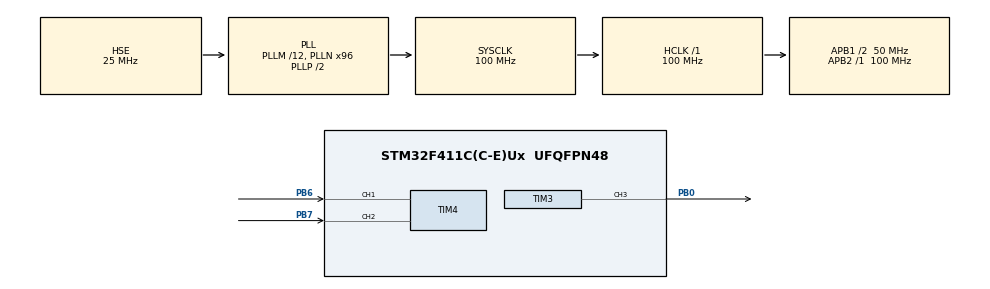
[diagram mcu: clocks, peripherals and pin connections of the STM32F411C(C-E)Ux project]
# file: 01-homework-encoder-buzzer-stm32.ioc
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Mcu.Family=STM32F4
Mcu.Name=STM32F411C(C-E)Ux
Mcu.Package=UFQFPN48
NVIC.PriorityGroup=NVIC_PRIORITYGROUP_4
PA13.Mode=Serial_Wire
PA13.Signal=SYS_JTMS-SWDIO
PA14.Mode=Serial_Wire
PA14.Signal=SYS_JTCK-SWCLK
PB0.Signal=S_TIM3_CH3
PB6.GPIO_PuPd=GPIO_PULLUP
PB6.Signal=S_TIM4_CH1
PB7.GPIO_PuPd=GPIO_PULLUP
PB7.Signal=S_TIM4_CH2
PH0\ -\ OSC_IN.Mode=HSE-External-Oscillator
PH0\ -\ OSC_IN.Signal=RCC_OSC_IN
PH1\ -\ OSC_OUT.Mode=HSE-External-Oscillator
PH1\ -\ OSC_OUT.Signal=RCC_OSC_OUT
ProjectManager.HeapSize=0x200
ProjectManager.StackSize=0x400
ProjectManager.TargetToolchain=STM32CubeIDE
RCC.48MHZClocksFreq_Value=50000000
RCC.AHBFreq_Value=100000000
RCC.APB1CLKDivider=RCC_HCLK_DIV2
RCC.APB1Freq_Value=50000000
RCC.APB1TimFreq_Value=100000000
RCC.APB2Freq_Value=100000000
RCC.APB2TimFreq_Value=100000000
RCC.CortexFreq_Value=100000000
RCC.HCLKFreq_Value=100000000
RCC.HSE_VALUE=25000000
RCC.HSI_VALUE=16000000
RCC.LSE_VALUE=32768
RCC.PLLM=12
RCC.PLLN=96
RCC.PLLSourceVirtual=RCC_PLLSOURCE_HSE
RCC.SYSCLKFreq_VALUE=100000000
RCC.SYSCLKSource=RCC_SYSCLKSOURCE_PLLCLK
RCC.VCOOutputFreq_Value=200000000
SH.S_TIM3_CH3.0=TIM3_CH3,PWM Generation3 CH3
SH.S_TIM4_CH1.0=TIM4_CH1,Encoder_Interface
SH.S_TIM4_CH2.0=TIM4_CH2,Encoder_Interface
TIM3.AutoReloadPreload=TIM_AUTORELOAD_PRELOAD_ENABLE
TIM3.Channel-PWM\ Generation3\ CH3=TIM_CHANNEL_3
TIM3.Period=999
TIM3.Prescaler=99
TIM3.Pulse-PWM\ Generation3\ CH3=500
board=custom

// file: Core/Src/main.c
/* USER CODE BEGIN Header */
/**
  ******************************************************************************
  * @file           : main.c
  * @brief          : Main program body
  ******************************************************************************
  * @attention
  *
  * Copyright (c) 2026 STMicroelectronics.
  * All rights reserved.
  *
  * This software is licensed under terms that can be found in the LICENSE file
  * in the root directory of this software component.
  * If no LICENSE file comes with this software, it is provided AS-IS.
  *
  ******************************************************************************
  */
/* USER CODE END Header */
#include "main.h"

/* USER CODE BEGIN PD */
#define BUZZER_TICK_HZ    1000000   // TIM3 counts at 1 MHz (100 MHz / (PSC 99 + 1))
#define BUZZER_START_ARR  999       // ARR 999 = a 1000 us period = 1 kHz
#define BUZZER_ARR_STEP   5         // ARR taken off per encoder count: counting up raises the tone, down lowers it
#define MELODY_POSITION   120       // about 3.3 turns up (measured: 108 counts in 3 turns): 2.5 kHz, then the melody
#define NOTE_GAP_MS       30        // silence after each note, so repeated notes (E E E) don't merge into one

// Notes of the 6th octave, in Hz
#define NOTE_C6  1047
#define NOTE_D6  1175
#define NOTE_E6  1319
#define NOTE_F6  1397
#define NOTE_G6  1568

// Note lengths, in ms
#define QUARTER         300
#define DOTTED_QUARTER  450
#define EIGHTH          150
#define HALF            600
#define WHOLE          1200
/* USER CODE END PD */

TIM_HandleTypeDef htim3;
TIM_HandleTypeDef htim4;

void SystemClock_Config(void);
static void MX_GPIO_Init(void);
static void MX_TIM3_Init(void);
static void MX_TIM4_Init(void);

/* USER CODE BEGIN 0 */
typedef struct {
  uint16_t hz;   // pitch
  uint16_t ms;   // length, the gap after it included
} Note;

// "Jingle Bells" (1857, public domain), the chorus twice
static const Note jingle_bells[] = {
  {NOTE_E6, QUARTER}, {NOTE_E6, QUARTER}, {NOTE_E6, HALF},
  {NOTE_E6, QUARTER}, {NOTE_E6, QUARTER}, {NOTE_E6, HALF},
  {NOTE_E6, QUARTER}, {NOTE_G6, QUARTER}, {NOTE_C6, DOTTED_QUARTER}, {NOTE_D6, EIGHTH},
  {NOTE_E6, WHOLE},
  {NOTE_F6, QUARTER}, {NOTE_F6, QUARTER}, {NOTE_F6, DOTTED_QUARTER}, {NOTE_F6, EIGHTH},
  {NOTE_F6, QUARTER}, {NOTE_E6, QUARTER}, {NOTE_E6, QUARTER}, {NOTE_E6, EIGHTH}, {NOTE_E6, EIGHTH},
  {NOTE_E6, QUARTER}, {NOTE_D6, QUARTER}, {NOTE_D6, QUARTER}, {NOTE_E6, QUARTER},
  {NOTE_D6, HALF}, {NOTE_G6, HALF},
  {NOTE_E6, QUARTER}, {NOTE_E6, QUARTER}, {NOTE_E6, HALF},
  {NOTE_E6, QUARTER}, {NOTE_E6, QUARTER}, {NOTE_E6, HALF},
  {NOTE_E6, QUARTER}, {NOTE_G6, QUARTER}, {NOTE_C6, DOTTED_QUARTER}, {NOTE_D6, EIGHTH},
  {NOTE_E6, WHOLE},
  {NOTE_F6, QUARTER}, {NOTE_F6, QUARTER}, {NOTE_F6, QUARTER}, {NOTE_F6, QUARTER},
  {NOTE_F6, QUARTER}, {NOTE_E6, QUARTER}, {NOTE_E6, QUARTER}, {NOTE_E6, EIGHTH}, {NOTE_E6, EIGHTH},
  {NOTE_G6, QUARTER}, {NOTE_G6, QUARTER}, {NOTE_F6, QUARTER}, {NOTE_D6, QUARTER},
  {NOTE_C6, WHOLE},
};

// Sets the buzzer's period in TIM3 ticks (1 us each) and keeps the duty at 50 %
static void buzzer_set_arr(uint32_t arr)
{
  __HAL_TIM_SET_AUTORELOAD(&htim3, arr);                          // preload on: starts when the current period ends
  __HAL_TIM_SET_COMPARE(&htim3, TIM_CHANNEL_3, (arr + 1) / 2);    // high for half the period
}

// Plays the whole melody; blocks for about 19 s, while TIM4 keeps counting the knob by itself
static void play_melody(void)
{
  for (uint32_t i = 0; i < sizeof(jingle_bells) / sizeof(jingle_bells[0]); i++) {
    buzzer_set_arr(BUZZER_TICK_HZ / jingle_bells[i].hz - 1);   // f = 1 MHz / (ARR + 1)
    HAL_Delay(jingle_bells[i].ms - NOTE_GAP_MS);
    __HAL_TIM_SET_COMPARE(&htim3, TIM_CHANNEL_3, 0);           // CCR 0: PB0 stays low, silence
    HAL_Delay(NOTE_GAP_MS);
  }
}
/* USER CODE END 0 */

int main(void)
{

  /* MCU Configuration--------------------------------------------------------*/

  /* Reset of all peripherals, Initializes the Flash interface and the Systick. */
  HAL_Init();

  /* Configure the system clock */
  SystemClock_Config();

  /* Initialize all configured peripherals */
  MX_GPIO_Init();
  MX_TIM3_Init();
  MX_TIM4_Init();
  /* USER CODE BEGIN 2 */
  HAL_TIM_PWM_Start(&htim3, TIM_CHANNEL_3);         // the buzzer: TIM3 drives PB0 by itself from now on
  HAL_TIM_Encoder_Start(&htim4, TIM_CHANNEL_ALL);   // the knob: TIM4 counts PB6/PB7 edges up or down by itself

  /* USER CODE END 2 */

  /* Infinite loop */
  while (1)
  {

    /* USER CODE BEGIN 3 */
    // TIM4's counter = where the knob is. Read as signed: one count below the start is -1, not 65535
    int16_t knob_position = (int16_t)__HAL_TIM_GET_COUNTER(&htim4);
    if (knob_position >= MELODY_POSITION) {
      play_melody();   // and again on the next pass, while the knob stays there
    } else {
      buzzer_set_arr(BUZZER_START_ARR - knob_position * BUZZER_ARR_STEP);   // smaller ARR = shorter period = higher tone
    }
  }
  /* USER CODE END 3 */
}

void SystemClock_Config(void)
{
  RCC_OscInitTypeDef RCC_OscInitStruct = {0};
  RCC_ClkInitTypeDef RCC_ClkInitStruct = {0};

  /** Configure the main internal regulator output voltage
  */
  __HAL_RCC_PWR_CLK_ENABLE();
  __HAL_PWR_VOLTAGESCALING_CONFIG(PWR_REGULATOR_VOLTAGE_SCALE1);

  /** Initializes the RCC Oscillators according to the specified parameters
  * in the RCC_OscInitTypeDef structure.
  */
  RCC_OscInitStruct.OscillatorType = RCC_OSCILLATORTYPE_HSE;
  RCC_OscInitStruct.HSEState = RCC_HSE_ON;
  RCC_OscInitStruct.PLL.PLLState = RCC_PLL_ON;
  RCC_OscInitStruct.PLL.PLLSource = RCC_PLLSOURCE_HSE;
  RCC_OscInitStruct.PLL.PLLM = 12;
  RCC_OscInitStruct.PLL.PLLN = 96;
  RCC_OscInitStruct.PLL.PLLP = RCC_PLLP_DIV2;
  RCC_OscInitStruct.PLL.PLLQ = 4;
  if (HAL_RCC_OscConfig(&RCC_OscInitStruct) != HAL_OK)
  {
    Error_Handler();
  }

  /** Initializes the CPU, AHB and APB buses clocks
  */
  RCC_ClkInitStruct.ClockType = RCC_CLOCKTYPE_HCLK|RCC_CLOCKTYPE_SYSCLK
                              |RCC_CLOCKTYPE_PCLK1|RCC_CLOCKTYPE_PCLK2;
  RCC_ClkInitStruct.SYSCLKSource = RCC_SYSCLKSOURCE_PLLCLK;
  RCC_ClkInitStruct.AHBCLKDivider = RCC_SYSCLK_DIV1;
  RCC_ClkInitStruct.APB1CLKDivider = RCC_HCLK_DIV2;
  RCC_ClkInitStruct.APB2CLKDivider = RCC_HCLK_DIV1;

  if (HAL_RCC_ClockConfig(&RCC_ClkInitStruct, FLASH_LATENCY_3) != HAL_OK)
  {
    Error_Handler();
  }
}

static void MX_TIM3_Init(void)
{

  TIM_MasterConfigTypeDef sMasterConfig = {0};
  TIM_OC_InitTypeDef sConfigOC = {0};

  htim3.Instance = TIM3;
  htim3.Init.Prescaler = 99;
  htim3.Init.CounterMode = TIM_COUNTERMODE_UP;
  htim3.Init.Period = 999;
  htim3.Init.ClockDivision = TIM_CLOCKDIVISION_DIV1;
  htim3.Init.AutoReloadPreload = TIM_AUTORELOAD_PRELOAD_ENABLE;
  if (HAL_TIM_PWM_Init(&htim3) != HAL_OK)
  {
    Error_Handler();
  }
  sMasterConfig.MasterOutputTrigger = TIM_TRGO_RESET;
  sMasterConfig.MasterSlaveMode = TIM_MASTERSLAVEMODE_DISABLE;
  if (HAL_TIMEx_MasterConfigSynchronization(&htim3, &sMasterConfig) != HAL_OK)
  {
    Error_Handler();
  }
  sConfigOC.OCMode = TIM_OCMODE_PWM1;
  sConfigOC.Pulse = 500;
  sConfigOC.OCPolarity = TIM_OCPOLARITY_HIGH;
  sConfigOC.OCFastMode = TIM_OCFAST_DISABLE;
  if (HAL_TIM_PWM_ConfigChannel(&htim3, &sConfigOC, TIM_CHANNEL_3) != HAL_OK)
  {
    Error_Handler();
  }
  HAL_TIM_MspPostInit(&htim3);

}

static void MX_TIM4_Init(void)
{

  TIM_Encoder_InitTypeDef sConfig = {0};
  TIM_MasterConfigTypeDef sMasterConfig = {0};

  htim4.Instance = TIM4;
  htim4.Init.Prescaler = 0;
  htim4.Init.CounterMode = TIM_COUNTERMODE_UP;
  htim4.Init.Period = 65535;
  htim4.Init.ClockDivision = TIM_CLOCKDIVISION_DIV1;
  htim4.Init.AutoReloadPreload = TIM_AUTORELOAD_PRELOAD_DISABLE;
  sConfig.EncoderMode = TIM_ENCODERMODE_TI1;
  sConfig.IC1Polarity = TIM_ICPOLARITY_RISING;
  sConfig.IC1Selection = TIM_ICSELECTION_DIRECTTI;
  sConfig.IC1Prescaler = TIM_ICPSC_DIV1;
  sConfig.IC1Filter = 0;
  sConfig.IC2Polarity = TIM_ICPOLARITY_RISING;
  sConfig.IC2Selection = TIM_ICSELECTION_DIRECTTI;
  sConfig.IC2Prescaler = TIM_ICPSC_DIV1;
  sConfig.IC2Filter = 0;
  if (HAL_TIM_Encoder_Init(&htim4, &sConfig) != HAL_OK)
  {
    Error_Handler();
  }
  sMasterConfig.MasterOutputTrigger = TIM_TRGO_RESET;
  sMasterConfig.MasterSlaveMode = TIM_MASTERSLAVEMODE_DISABLE;
  if (HAL_TIMEx_MasterConfigSynchronization(&htim4, &sMasterConfig) != HAL_OK)
  {
    Error_Handler();
  }

}

static void MX_GPIO_Init(void)
{

  /* GPIO Ports Clock Enable */
  __HAL_RCC_GPIOH_CLK_ENABLE();
  __HAL_RCC_GPIOB_CLK_ENABLE();
  __HAL_RCC_GPIOA_CLK_ENABLE();

}

void Error_Handler(void)
{
  __disable_irq();
  while (1)
  {
  }
}
